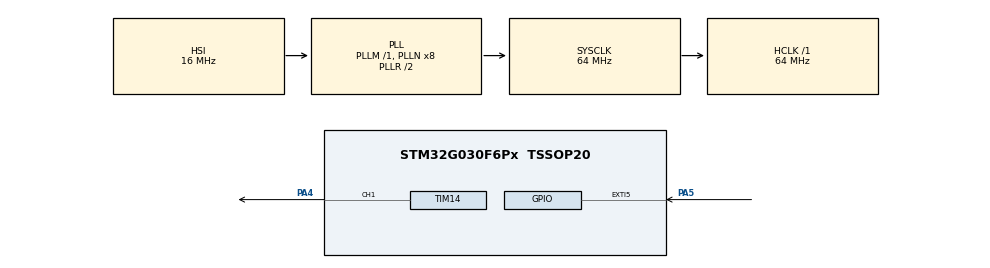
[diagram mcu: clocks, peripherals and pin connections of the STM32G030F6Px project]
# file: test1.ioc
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Mcu.Family=STM32G0
Mcu.Name=STM32G030F6Px
Mcu.Package=TSSOP20
NVIC.EXTI4_15_IRQn=true\:0\:0\:false\:true\:true\:1\:true\:true
NVIC.TIM14_IRQn=true\:0\:0\:false\:false\:true\:true\:true
PA13.Mode=Serial_Wire
PA13.Signal=SYS_SWDIO
PA14-BOOT0.Mode=Serial_Wire
PA14-BOOT0.Signal=SYS_SWCLK
PA4.Signal=S_TIM14_CH1
PA5.Signal=GPXTI5
ProjectManager.HeapSize=0x200
ProjectManager.StackSize=0x400
ProjectManager.TargetToolchain=MDK-ARM V5.32
RCC.ADCFreq_Value=64000000
RCC.AHBFreq_Value=64000000
RCC.CortexFreq_Value=64000000
RCC.EXTERNAL_CLOCK_VALUE=12288000
RCC.HCLKFreq_Value=64000000
RCC.HSE_VALUE=8000000
RCC.HSI_VALUE=16000000
RCC.LSE_VALUE=32768
RCC.SYSCLKFreq_VALUE=64000000
RCC.SYSCLKSource=RCC_SYSCLKSOURCE_PLLCLK
RCC.VCOOutputFreq_Value=128000000
SH.S_TIM14_CH1.0=TIM14_CH1,PWM Generation1 CH1
TIM14.Channel=TIM_CHANNEL_1
TIM14.Period=999
TIM14.Prescaler=63
TIM14.Pulse=50
TIM16.Period=9999
TIM16.Prescaler=6399
VP_TIM14_VS_ClockSourceINT.Mode=Enable_Timer
VP_TIM16_VS_ClockSourceINT.Mode=Enable_Timer
board=custom

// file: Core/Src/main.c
/* USER CODE BEGIN Header */
/**
  ******************************************************************************
  * @file           : main.c
  * @brief          : Main program body
  ******************************************************************************
  * @attention
  *
  * <h2><center>&copy; Copyright (c) 2021 STMicroelectronics.
  * All rights reserved.</center></h2>
  *
  * This software component is licensed by ST under BSD 3-Clause license,
  * the "License"; You may not use this file except in compliance with the
  * License. You may obtain a copy of the License at:
  *                        opensource.org/licenses/BSD-3-Clause
  *
  ******************************************************************************
  */
/* USER CODE END Header */
#include "main.h"
#include "tim.h"
#include "gpio.h"

void SystemClock_Config(void);
static void MX_NVIC_Init(void);

int main(void)
{

  /* MCU Configuration--------------------------------------------------------*/

  /* Reset of all peripherals, Initializes the Flash interface and the Systick. */
  HAL_Init();

  /* Configure the system clock */
  SystemClock_Config();

  /* Initialize all configured peripherals */
  MX_GPIO_Init();
  MX_TIM14_Init();
  MX_TIM16_Init();

  /* Initialize interrupts */
  MX_NVIC_Init();
  /* USER CODE BEGIN 2 */
	HAL_TIM_Base_Start(&htim16);
	HAL_TIM_PWM_Start(&htim14,TIM_CHANNEL_1);

  /* USER CODE END 2 */

  /* Infinite loop */
  while (1)
  {

  }
}

void SystemClock_Config(void)
{
  RCC_OscInitTypeDef RCC_OscInitStruct = {0};
  RCC_ClkInitTypeDef RCC_ClkInitStruct = {0};

  /** Configure the main internal regulator output voltage
  */
  HAL_PWREx_ControlVoltageScaling(PWR_REGULATOR_VOLTAGE_SCALE1);
  /** Initializes the RCC Oscillators according to the specified parameters
  * in the RCC_OscInitTypeDef structure.
  */
  RCC_OscInitStruct.OscillatorType = RCC_OSCILLATORTYPE_HSI;
  RCC_OscInitStruct.HSIState = RCC_HSI_ON;
  RCC_OscInitStruct.HSIDiv = RCC_HSI_DIV1;
  RCC_OscInitStruct.HSICalibrationValue = RCC_HSICALIBRATION_DEFAULT;
  RCC_OscInitStruct.PLL.PLLState = RCC_PLL_ON;
  RCC_OscInitStruct.PLL.PLLSource = RCC_PLLSOURCE_HSI;
  RCC_OscInitStruct.PLL.PLLM = RCC_PLLM_DIV1;
  RCC_OscInitStruct.PLL.PLLN = 8;
  RCC_OscInitStruct.PLL.PLLP = RCC_PLLP_DIV2;
  RCC_OscInitStruct.PLL.PLLR = RCC_PLLR_DIV2;
  if (HAL_RCC_OscConfig(&RCC_OscInitStruct) != HAL_OK)
  {
    Error_Handler();
  }
  /** Initializes the CPU, AHB and APB buses clocks
  */
  RCC_ClkInitStruct.ClockType = RCC_CLOCKTYPE_HCLK|RCC_CLOCKTYPE_SYSCLK
                              |RCC_CLOCKTYPE_PCLK1;
  RCC_ClkInitStruct.SYSCLKSource = RCC_SYSCLKSOURCE_PLLCLK;
  RCC_ClkInitStruct.AHBCLKDivider = RCC_SYSCLK_DIV1;
  RCC_ClkInitStruct.APB1CLKDivider = RCC_HCLK_DIV1;

  if (HAL_RCC_ClockConfig(&RCC_ClkInitStruct, FLASH_LATENCY_2) != HAL_OK)
  {
    Error_Handler();
  }
}

/**
  * @brief NVIC Configuration.
  * @retval None
  */
static void MX_NVIC_Init(void)
{
  /* EXTI4_15_IRQn interrupt configuration */
  HAL_NVIC_SetPriority(EXTI4_15_IRQn, 0, 0);
  HAL_NVIC_EnableIRQ(EXTI4_15_IRQn);
}

/* USER CODE BEGIN 4 */
volatile uint16_t timer_val1,timer_val2,timer_diff;
uint32_t c=0;
void HAL_GPIO_EXTI_Rising_Callback(uint16_t GPIO_Pin)
{
	if(GPIO_Pin==GPIO_PIN_5)
	{
		//tim14分频后的时钟频率是1Mhz，PWM的频率是1Khz，两个相邻上升沿间隔千分之一秒
		//tim16分频后的始终频率是10Khz，所以千分之一秒相差计数器的值为10
		timer_val1=timer_val2;
		timer_val2=__HAL_TIM_GET_COUNTER(&htim16);
		timer_diff=timer_val2-timer_val1;
		if(timer_val2<timer_val1){
			timer_diff=10000-timer_val1+timer_val2+1;

		}
		if(timer_diff>20 || timer_diff<5){
			c++;
		}
	}
}
/* USER CODE END 4 */

void Error_Handler(void)
{
  __disable_irq();
  while (1)
  {
  }
}

/************************ (C) COPYRIGHT STMicroelectronics *****END OF FILE****/
